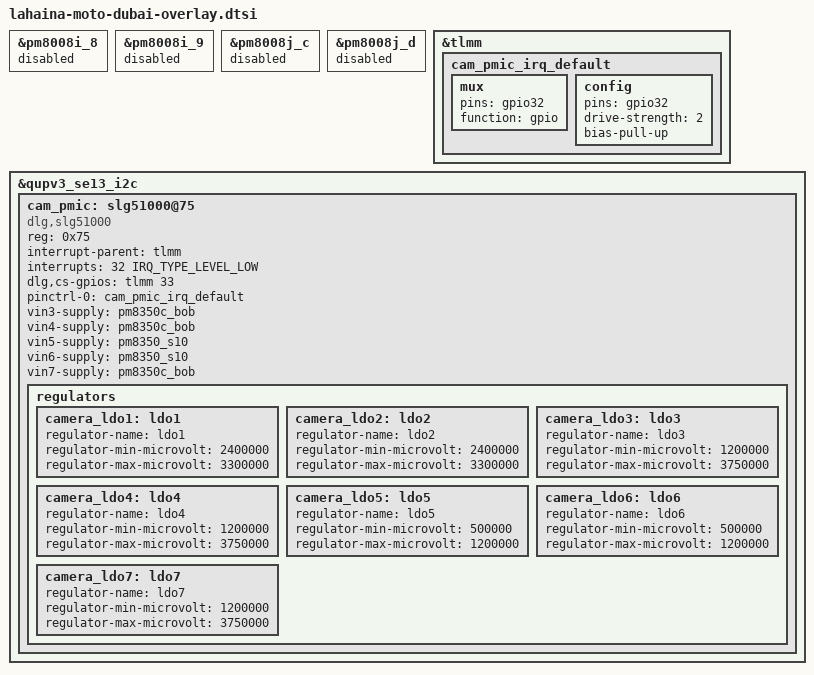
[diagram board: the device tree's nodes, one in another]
/* Copyright (c) 2020, The Linux Foundation. All rights reserved.
 *
 * This program is free software; you can redistribute it and/or modify
 * it under the terms of the GNU General Public License version 2 and
 * only version 2 as published by the Free Software Foundation.
 *
 * This program is distributed in the hope that it will be useful,
 * but WITHOUT ANY WARRANTY; without even the implied warranty of
 * MERCHANTABILITY or FITNESS FOR A PARTICULAR PURPOSE.  See the
 * GNU General Public License for more details.
 */

#include "lahaina-moto-common-overlay.dtsi"
#include "lahaina-dubai-fingerprint.dtsi"
#include "lahaina-moto-dubai-display.dtsi"
#include "camera/lahaina-camera-sensor-mot-dubai-overlay.dtsi"

&pm8008i_8 {
	status = "disabled";
};

&pm8008i_9 {
	status = "disabled";
};

&pm8008j_c {
	status = "disabled";
};

&pm8008j_d {
	status = "disabled";
};

&tlmm{
	cam_pmic_irq_default: cam_pmic_irq_default {
		mux {
			pins = "gpio32";
			function = "gpio";
		};
		config {
		        pins = "gpio32";
			drive-strength = <2>; /* 2 mA */
			bias-pull-up;
		};
	};
};

&qupv3_se13_i2c {
	status = "ok";

	cam_pmic: slg51000@75 {
		compatible = "dlg,slg51000";
		reg = <0x75>;

		interrupt-parent = <&tlmm>;
		interrupts = <32 IRQ_TYPE_LEVEL_LOW>;

		dlg,cs-gpios = <&tlmm 33 0>;

		pinctrl-names = "pmic_default";
		pinctrl-0 = <&cam_pmic_irq_default>;

		vin3-supply = <&pm8350c_bob>;
		vin4-supply = <&pm8350c_bob>;
		vin5-supply = <&pm8350_s10>;
		vin6-supply = <&pm8350_s10>;
		vin7-supply = <&pm8350c_bob>;

		regulators {
			camera_ldo1: ldo1 {
				regulator-name = "ldo1";
				regulator-min-microvolt = <2400000>;
				regulator-max-microvolt = <3300000>;
			};

			camera_ldo2: ldo2 {
				regulator-name = "ldo2";
				regulator-min-microvolt = <2400000>;
				regulator-max-microvolt = <3300000>;
			};

			camera_ldo3: ldo3 {
				regulator-name = "ldo3";
				regulator-min-microvolt = <1200000>;
				regulator-max-microvolt = <3750000>;
			};

			camera_ldo4: ldo4 {
				regulator-name = "ldo4";
				regulator-min-microvolt = <1200000>;
				regulator-max-microvolt = <3750000>;
			};

			camera_ldo5: ldo5 {
				regulator-name = "ldo5";
				regulator-min-microvolt = <500000>;
				regulator-max-microvolt = <1200000>;
			};

			camera_ldo6: ldo6 {
				regulator-name = "ldo6";
				regulator-min-microvolt = <500000>;
				regulator-max-microvolt = <1200000>;
			};

			camera_ldo7: ldo7 {
				regulator-name = "ldo7";
				regulator-min-microvolt = <1200000>;
				regulator-max-microvolt = <3750000>;
			};
		};
	};
};
